VERSION ""

NS_ :

BS_:

BU_: ECU1

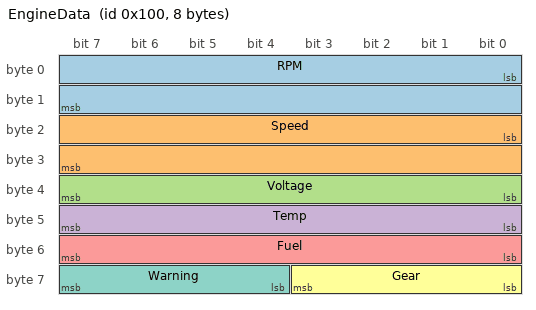
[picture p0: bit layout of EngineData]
BO_ 256 EngineData: 8 ECU1
 SG_ RPM      : 0|16@1+ (0.125,0) [0|8000] "" Vector__XXX
 SG_ Speed    : 16|16@1+ (0.01,0)  [0|250]  "" Vector__XXX
 SG_ Voltage  : 32|8@1+  (0.1,0)   [0|25.5] "" Vector__XXX
 SG_ Temp     : 40|8@1+  (1,0)     [0|255]  "" Vector__XXX
 SG_ Fuel     : 48|8@1+  (1,0)     [0|100]  "" Vector__XXX
 SG_ Gear     : 56|4@1+  (1,0)     [0|15]   "" Vector__XXX
 SG_ Warning  : 60|4@1+  (1,0)     [0|15]   "" Vector__XXX
